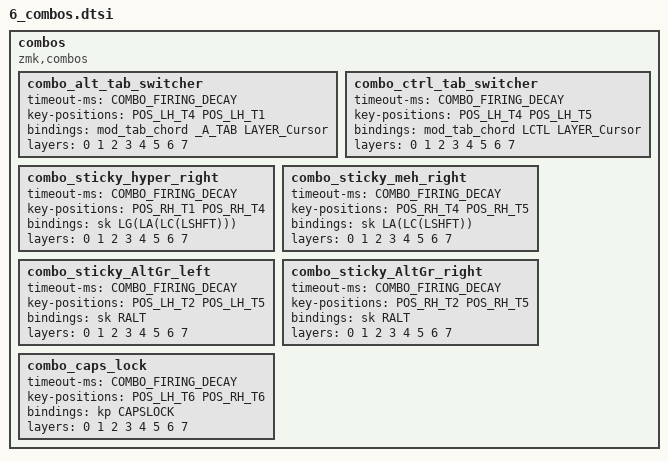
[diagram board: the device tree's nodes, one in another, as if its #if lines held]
combos {
  compatible = "zmk,combos";

  //
  // COMBO_FIRING_DECAY defines how much time you have left (milliseconds)
  // after pressing the first key in a ZMK combo to finish the whole chord.
  //
  #ifndef COMBO_FIRING_DECAY
  #define COMBO_FIRING_DECAY 50
  #endif
  #ifdef LAYER_Cursor
  #ifdef _A_TAB
  combo_alt_tab_switcher {
    timeout-ms = <COMBO_FIRING_DECAY>;
    key-positions = <POS_LH_T4 POS_LH_T1>;
    bindings = <&mod_tab_chord _A_TAB LAYER_Cursor>;
    layers = <0 1 2 3 4 5 6 7>;
  };
  #endif

  combo_ctrl_tab_switcher {
    timeout-ms = <COMBO_FIRING_DECAY>;
    key-positions = <POS_LH_T4 POS_LH_T5>;
    bindings = <&mod_tab_chord LCTL LAYER_Cursor>;
    layers = <0 1 2 3 4 5 6 7>;
  };
  #endif

  combo_sticky_hyper_right {
    timeout-ms = <COMBO_FIRING_DECAY>;
    key-positions = <POS_RH_T1 POS_RH_T4>;
    bindings = <&sk LG(LA(LC(LSHFT)))>;
    layers = <0 1 2 3 4 5 6 7>;
  };

  combo_sticky_meh_right {
    timeout-ms = <COMBO_FIRING_DECAY>;
    key-positions = <POS_RH_T4 POS_RH_T5>;
    bindings = <&sk LA(LC(LSHFT))>;
    layers = <0 1 2 3 4 5 6 7>;
  };

  combo_sticky_AltGr_left {
    timeout-ms = <COMBO_FIRING_DECAY>;
    key-positions = <POS_LH_T2 POS_LH_T5>;
    bindings = <&sk RALT>;
    layers = <0 1 2 3 4 5 6 7>;
  };

  combo_sticky_AltGr_right {
    timeout-ms = <COMBO_FIRING_DECAY>;
    key-positions = <POS_RH_T2 POS_RH_T5>;
    bindings = <&sk RALT>;
    layers = <0 1 2 3 4 5 6 7>;
  };

  combo_caps_lock {
    timeout-ms = <COMBO_FIRING_DECAY>;
    key-positions = <POS_LH_T6 POS_RH_T6>;
    bindings = <&kp CAPSLOCK>;
    layers = <0 1 2 3 4 5 6 7>;
  };

};

